VERSION ""

NS_ :

BS_:

BU_: Radar MABX

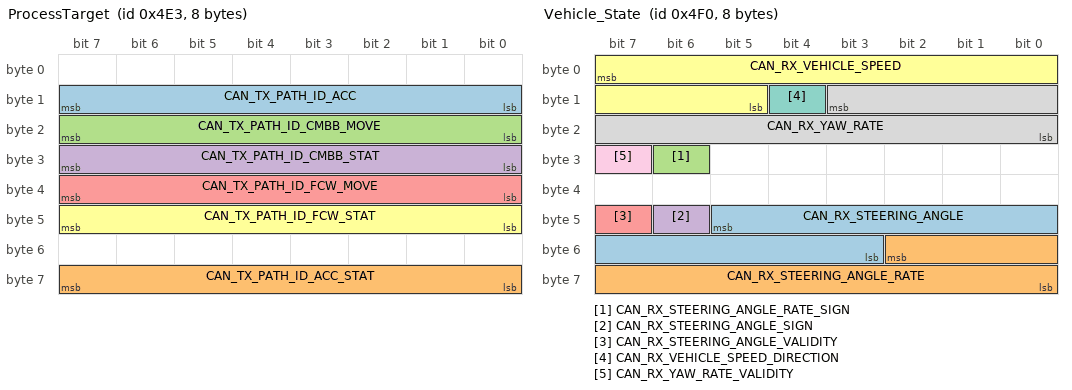
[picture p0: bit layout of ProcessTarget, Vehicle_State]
BO_ 1251 ProcessTarget: 8 Radar
 SG_ CAN_TX_PATH_ID_ACC : 15|8@0+ (1,0) [0|255] ""  MABX
 SG_ CAN_TX_PATH_ID_ACC_STAT : 63|8@0+ (1,0) [0|255] ""  MABX
 SG_ CAN_TX_PATH_ID_CMBB_MOVE : 23|8@0+ (1,0) [0|255] ""  MABX
 SG_ CAN_TX_PATH_ID_CMBB_STAT : 31|8@0+ (1,0) [0|255] ""  MABX
 SG_ CAN_TX_PATH_ID_FCW_MOVE : 39|8@0+ (1,0) [0|255] ""  MABX
 SG_ CAN_TX_PATH_ID_FCW_STAT : 47|8@0+ (1,0) [0|255] ""  MABX

BO_ 1264 Vehicle_State: 8 MABX
 SG_ CAN_RX_STEERING_ANGLE : 45|11@0+ (1,0) [0|2047] "deg"  Radar
 SG_ CAN_RX_STEERING_ANGLE_RATE : 50|11@0+ (1,0) [0|2047] "deg/s"  Radar
 SG_ CAN_RX_STEERING_ANGLE_RATE_SIGN : 30|1@0+ (1,0) [0|1] ""  Radar
 SG_ CAN_RX_STEERING_ANGLE_SIGN : 46|1@0+ (1,0) [0|1] ""  Radar
 SG_ CAN_RX_STEERING_ANGLE_VALIDITY : 47|1@0+ (1,0) [0|1] ""  Radar
 SG_ CAN_RX_VEHICLE_SPEED : 7|11@0+ (0.0625,0) [0|127.9375] "m/s"  Radar
 SG_ CAN_RX_VEHICLE_SPEED_DIRECTION : 12|1@0+ (1,0) [0|1] ""  Radar
 SG_ CAN_RX_YAW_RATE : 11|12@0- (0.0625,0) [-128|127.9375] "deg/s"  Radar
 SG_ CAN_RX_YAW_RATE_VALIDITY : 31|1@0+ (1,0) [0|1] ""  Radar

BO_ 1265 Radar_Lateral_Position: 8 MABX
 SG_ CAN_RX_LATERAL_MOUNTING_OFFSET : 47|8@0- (0.015625,0) [-1.9375|1.9375] "m"  Radar
 SG_ CAN_RX_VEHICLE_SPEED_VALIDITY : 61|1@0+ (1,0) [0|1] ""  Radar

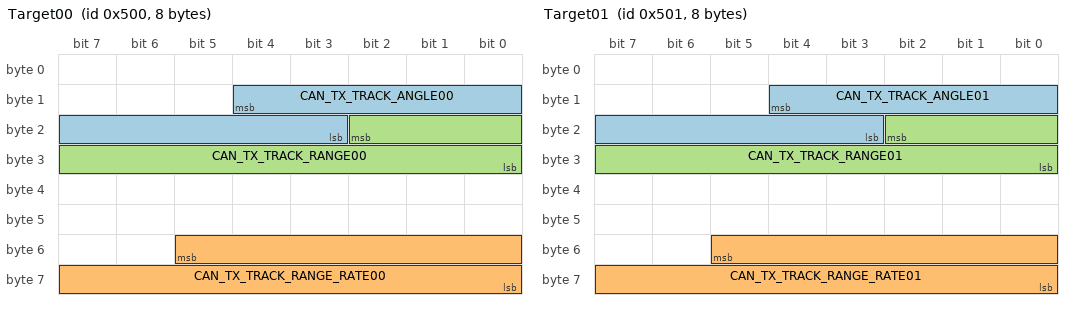
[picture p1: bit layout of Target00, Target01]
BO_ 1280 Target00: 8 Radar
 SG_ CAN_TX_TRACK_ANGLE00 : 12|10@0- (0.1,0) [-51.2|51.1] "deg"  MABX
 SG_ CAN_TX_TRACK_RANGE_RATE00 : 53|14@0- (0.01,0) [-81.92|81.92] "m/s"  MABX
 SG_ CAN_TX_TRACK_RANGE00 : 18|11@0+ (0.1,0) [0|204.7] "m"  MABX

BO_ 1281 Target01: 8 Radar
 SG_ CAN_TX_TRACK_ANGLE01 : 12|10@0- (0.1,0) [-51.2|51.1] "deg"  MABX
 SG_ CAN_TX_TRACK_RANGE_RATE01 : 53|14@0- (0.01,0) [-81.92|81.92] "m/s"  MABX
 SG_ CAN_TX_TRACK_RANGE01 : 18|11@0+ (0.1,0) [0|204.7] "m"  MABX

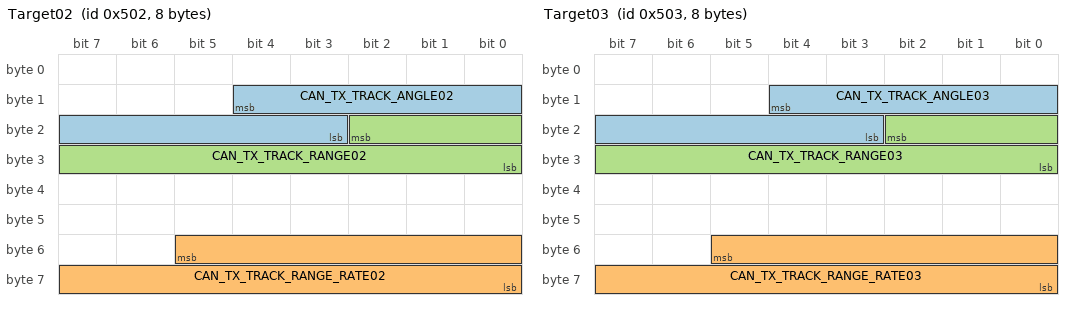
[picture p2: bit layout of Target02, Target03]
BO_ 1282 Target02: 8 Radar
 SG_ CAN_TX_TRACK_ANGLE02 : 12|10@0- (0.1,0) [-51.2|51.1] "deg"  MABX
 SG_ CAN_TX_TRACK_RANGE_RATE02 : 53|14@0- (0.01,0) [-81.92|81.92] "m/s"  MABX
 SG_ CAN_TX_TRACK_RANGE02 : 18|11@0+ (0.1,0) [0|204.7] "m"  MABX

BO_ 1283 Target03: 8 Radar
 SG_ CAN_TX_TRACK_ANGLE03 : 12|10@0- (0.1,0) [-51.2|51.1] "deg"  MABX
 SG_ CAN_TX_TRACK_RANGE_RATE03 : 53|14@0- (0.01,0) [-81.92|81.92] "m/s"  MABX
 SG_ CAN_TX_TRACK_RANGE03 : 18|11@0+ (0.1,0) [0|204.7] "m"  MABX

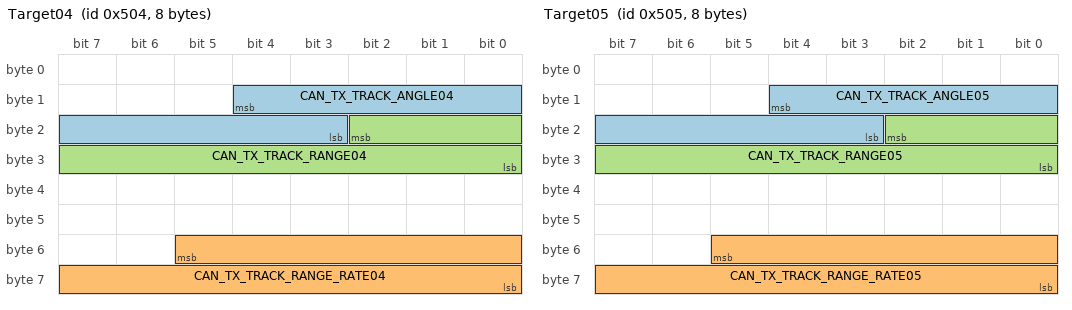
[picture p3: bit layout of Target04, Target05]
BO_ 1284 Target04: 8 Radar
 SG_ CAN_TX_TRACK_ANGLE04 : 12|10@0- (0.1,0) [-51.2|51.1] "deg"  MABX
 SG_ CAN_TX_TRACK_RANGE_RATE04 : 53|14@0- (0.01,0) [-81.92|81.92] "m/s"  MABX
 SG_ CAN_TX_TRACK_RANGE04 : 18|11@0+ (0.1,0) [0|204.7] "m"  MABX

BO_ 1285 Target05: 8 Radar
 SG_ CAN_TX_TRACK_ANGLE05 : 12|10@0- (0.1,0) [-51.2|51.1] "deg"  MABX
 SG_ CAN_TX_TRACK_RANGE_RATE05 : 53|14@0- (0.01,0) [-81.92|81.92] "m/s"  MABX
 SG_ CAN_TX_TRACK_RANGE05 : 18|11@0+ (0.1,0) [0|204.7] "m"  MABX

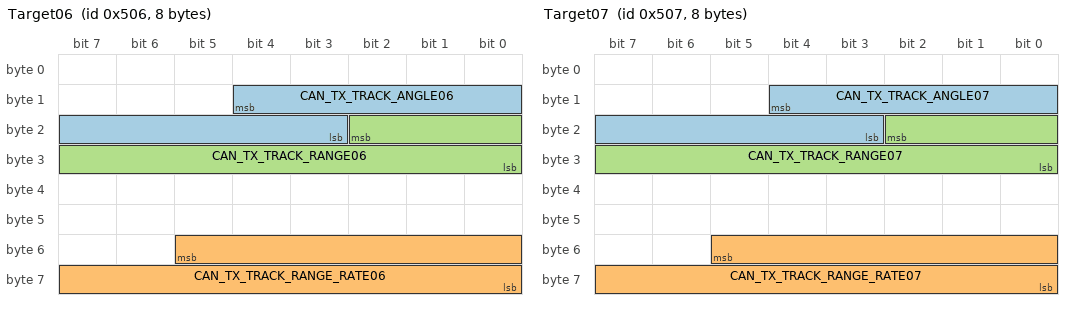
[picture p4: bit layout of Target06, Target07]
BO_ 1286 Target06: 8 Radar
 SG_ CAN_TX_TRACK_ANGLE06 : 12|10@0- (0.1,0) [-51.2|51.1] "deg"  MABX
 SG_ CAN_TX_TRACK_RANGE_RATE06 : 53|14@0- (0.01,0) [-81.92|81.92] "m/s"  MABX
 SG_ CAN_TX_TRACK_RANGE06 : 18|11@0+ (0.1,0) [0|204.7] "m"  MABX

BO_ 1287 Target07: 8 Radar
 SG_ CAN_TX_TRACK_ANGLE07 : 12|10@0- (0.1,0) [-51.2|51.1] "deg"  MABX
 SG_ CAN_TX_TRACK_RANGE_RATE07 : 53|14@0- (0.01,0) [-81.92|81.92] "m/s"  MABX
 SG_ CAN_TX_TRACK_RANGE07 : 18|11@0+ (0.1,0) [0|204.7] "m"  MABX

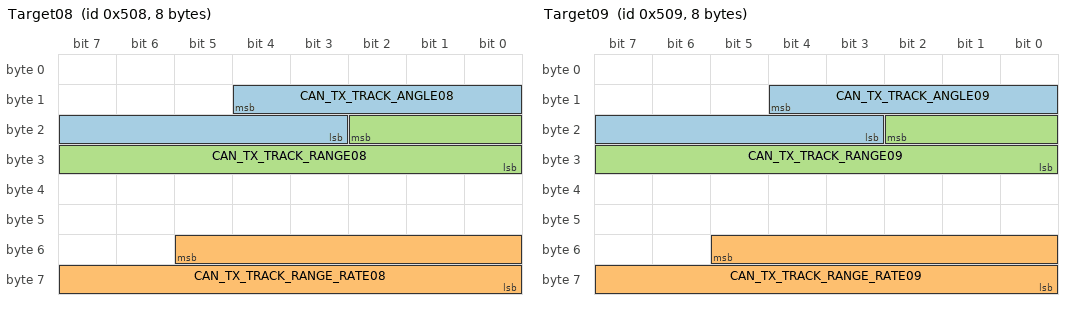
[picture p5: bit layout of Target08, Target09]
BO_ 1288 Target08: 8 Radar
 SG_ CAN_TX_TRACK_ANGLE08 : 12|10@0- (0.1,0) [-51.2|51.1] "deg"  MABX
 SG_ CAN_TX_TRACK_RANGE_RATE08 : 53|14@0- (0.01,0) [-81.92|81.92] "m/s"  MABX
 SG_ CAN_TX_TRACK_RANGE08 : 18|11@0+ (0.1,0) [0|204.7] "m"  MABX

BO_ 1289 Target09: 8 Radar
 SG_ CAN_TX_TRACK_ANGLE09 : 12|10@0- (0.1,0) [-51.2|51.1] "deg"  MABX
 SG_ CAN_TX_TRACK_RANGE_RATE09 : 53|14@0- (0.01,0) [-81.92|81.92] "m/s"  MABX
 SG_ CAN_TX_TRACK_RANGE09 : 18|11@0+ (0.1,0) [0|204.7] "m"  MABX

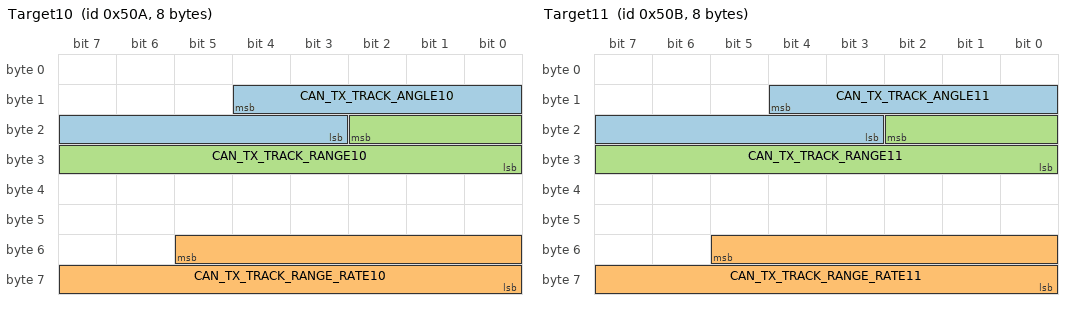
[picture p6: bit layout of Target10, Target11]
BO_ 1290 Target10: 8 Radar
 SG_ CAN_TX_TRACK_ANGLE10 : 12|10@0- (0.1,0) [-51.2|51.1] "deg"  MABX
 SG_ CAN_TX_TRACK_RANGE_RATE10 : 53|14@0- (0.01,0) [-81.92|81.92] "m/s"  MABX
 SG_ CAN_TX_TRACK_RANGE10 : 18|11@0+ (0.1,0) [0|204.7] "m"  MABX

BO_ 1291 Target11: 8 Radar
 SG_ CAN_TX_TRACK_ANGLE11 : 12|10@0- (0.1,0) [-51.2|51.1] "deg"  MABX
 SG_ CAN_TX_TRACK_RANGE_RATE11 : 53|14@0- (0.01,0) [-81.92|81.92] "m/s"  MABX
 SG_ CAN_TX_TRACK_RANGE11 : 18|11@0+ (0.1,0) [0|204.7] "m"  MABX

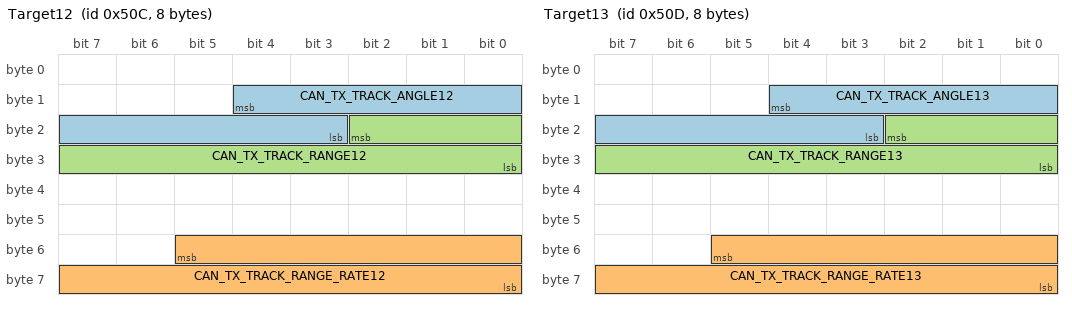
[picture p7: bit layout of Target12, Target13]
BO_ 1292 Target12: 8 Radar
 SG_ CAN_TX_TRACK_ANGLE12 : 12|10@0- (0.1,0) [-51.2|51.1] "deg"  MABX
 SG_ CAN_TX_TRACK_RANGE_RATE12 : 53|14@0- (0.01,0) [-81.92|81.92] "m/s"  MABX
 SG_ CAN_TX_TRACK_RANGE12 : 18|11@0+ (0.1,0) [0|204.7] "m"  MABX

BO_ 1293 Target13: 8 Radar
 SG_ CAN_TX_TRACK_ANGLE13 : 12|10@0- (0.1,0) [-51.2|51.1] "deg"  MABX
 SG_ CAN_TX_TRACK_RANGE_RATE13 : 53|14@0- (0.01,0) [-81.92|81.92] "m/s"  MABX
 SG_ CAN_TX_TRACK_RANGE13 : 18|11@0+ (0.1,0) [0|204.7] "m"  MABX

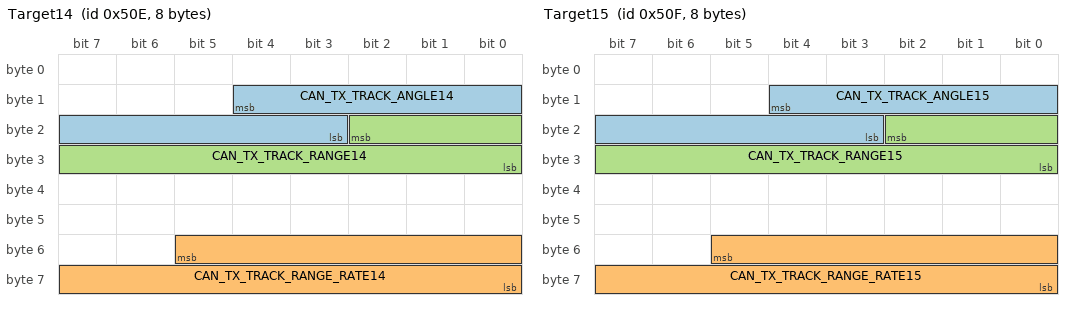
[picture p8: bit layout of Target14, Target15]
BO_ 1294 Target14: 8 Radar
 SG_ CAN_TX_TRACK_ANGLE14 : 12|10@0- (0.1,0) [-51.2|51.1] "deg"  MABX
 SG_ CAN_TX_TRACK_RANGE_RATE14 : 53|14@0- (0.01,0) [-81.92|81.92] "m/s"  MABX
 SG_ CAN_TX_TRACK_RANGE14 : 18|11@0+ (0.1,0) [0|204.7] "m"  MABX

BO_ 1295 Target15: 8 Radar
 SG_ CAN_TX_TRACK_ANGLE15 : 12|10@0- (0.1,0) [-51.2|51.1] "deg"  MABX
 SG_ CAN_TX_TRACK_RANGE_RATE15 : 53|14@0- (0.01,0) [-81.92|81.92] "m/s"  MABX
 SG_ CAN_TX_TRACK_RANGE15 : 18|11@0+ (0.1,0) [0|204.7] "m"  MABX

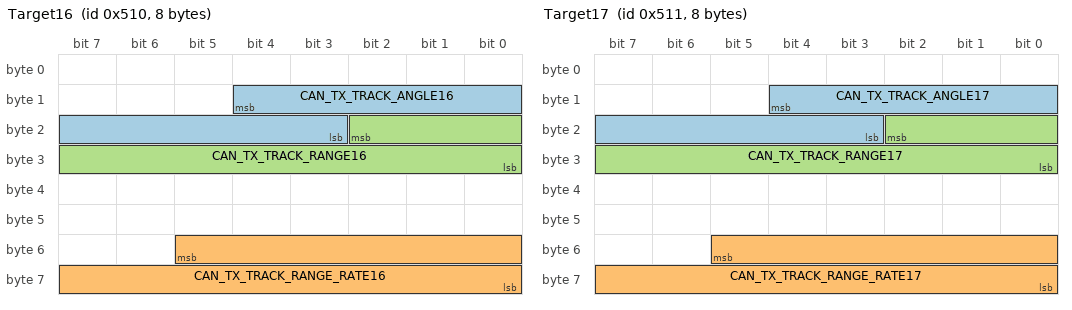
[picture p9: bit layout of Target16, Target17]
BO_ 1296 Target16: 8 Radar
 SG_ CAN_TX_TRACK_ANGLE16 : 12|10@0- (0.1,0) [-51.2|51.1] "deg"  MABX
 SG_ CAN_TX_TRACK_RANGE_RATE16 : 53|14@0- (0.01,0) [-81.92|81.92] "m/s"  MABX
 SG_ CAN_TX_TRACK_RANGE16 : 18|11@0+ (0.1,0) [0|204.7] "m"  MABX

BO_ 1297 Target17: 8 Radar
 SG_ CAN_TX_TRACK_ANGLE17 : 12|10@0- (0.1,0) [-51.2|51.1] "deg"  MABX
 SG_ CAN_TX_TRACK_RANGE_RATE17 : 53|14@0- (0.01,0) [-81.92|81.92] "m/s"  MABX
 SG_ CAN_TX_TRACK_RANGE17 : 18|11@0+ (0.1,0) [0|204.7] "m"  MABX

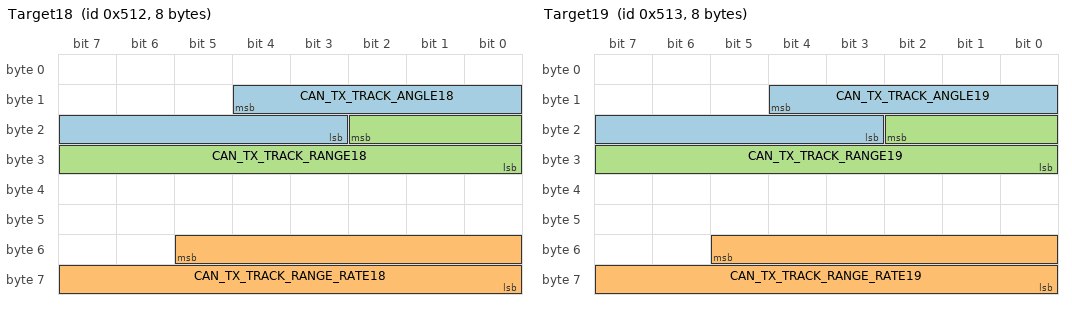
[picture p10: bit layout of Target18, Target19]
BO_ 1298 Target18: 8 Radar
 SG_ CAN_TX_TRACK_ANGLE18 : 12|10@0- (0.1,0) [-51.2|51.1] "deg"  MABX
 SG_ CAN_TX_TRACK_RANGE_RATE18 : 53|14@0- (0.01,0) [-81.92|81.92] "m/s"  MABX
 SG_ CAN_TX_TRACK_RANGE18 : 18|11@0+ (0.1,0) [0|204.7] "m"  MABX

BO_ 1299 Target19: 8 Radar
 SG_ CAN_TX_TRACK_ANGLE19 : 12|10@0- (0.1,0) [-51.2|51.1] "deg"  MABX
 SG_ CAN_TX_TRACK_RANGE_RATE19 : 53|14@0- (0.01,0) [-81.92|81.92] "m/s"  MABX
 SG_ CAN_TX_TRACK_RANGE19 : 18|11@0+ (0.1,0) [0|204.7] "m"  MABX

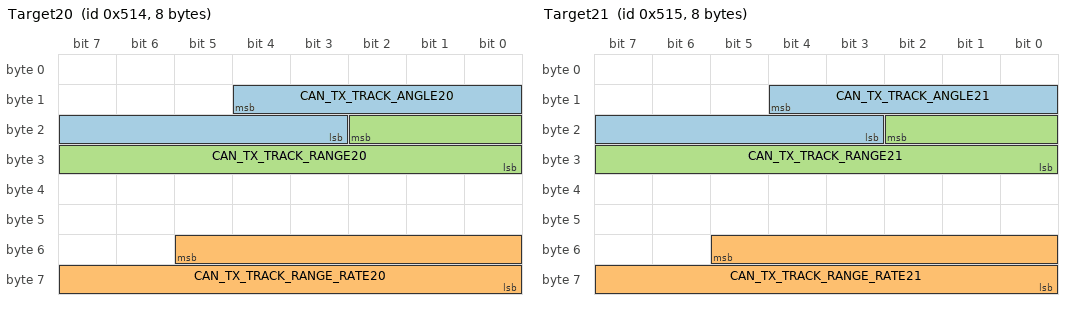
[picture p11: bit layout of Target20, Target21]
BO_ 1300 Target20: 8 Radar
 SG_ CAN_TX_TRACK_ANGLE20 : 12|10@0- (0.1,0) [-51.2|51.1] "deg"  MABX
 SG_ CAN_TX_TRACK_RANGE_RATE20 : 53|14@0- (0.01,0) [-81.92|81.92] "m/s"  MABX
 SG_ CAN_TX_TRACK_RANGE20 : 18|11@0+ (0.1,0) [0|204.7] "m"  MABX

BO_ 1301 Target21: 8 Radar
 SG_ CAN_TX_TRACK_ANGLE21 : 12|10@0- (0.1,0) [-51.2|51.1] "deg"  MABX
 SG_ CAN_TX_TRACK_RANGE_RATE21 : 53|14@0- (0.01,0) [-81.92|81.92] "m/s"  MABX
 SG_ CAN_TX_TRACK_RANGE21 : 18|11@0+ (0.1,0) [0|204.7] "m"  MABX

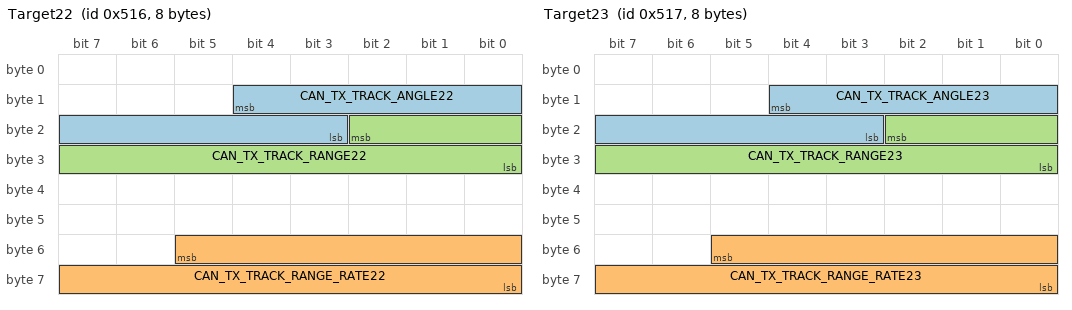
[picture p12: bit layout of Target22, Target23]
BO_ 1302 Target22: 8 Radar
 SG_ CAN_TX_TRACK_ANGLE22 : 12|10@0- (0.1,0) [-51.2|51.1] "deg"  MABX
 SG_ CAN_TX_TRACK_RANGE_RATE22 : 53|14@0- (0.01,0) [-81.92|81.92] "m/s"  MABX
 SG_ CAN_TX_TRACK_RANGE22 : 18|11@0+ (0.1,0) [0|204.7] "m"  MABX

BO_ 1303 Target23: 8 Radar
 SG_ CAN_TX_TRACK_ANGLE23 : 12|10@0- (0.1,0) [-51.2|51.1] "deg"  MABX
 SG_ CAN_TX_TRACK_RANGE_RATE23 : 53|14@0- (0.01,0) [-81.92|81.92] "m/s"  MABX
 SG_ CAN_TX_TRACK_RANGE23 : 18|11@0+ (0.1,0) [0|204.7] "m"  MABX

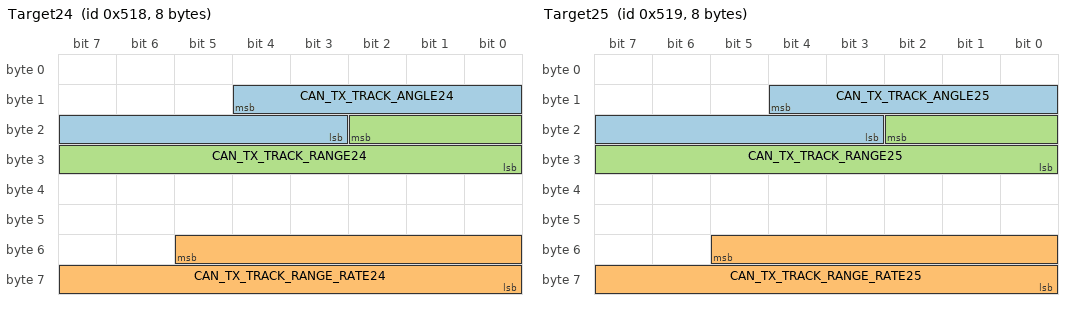
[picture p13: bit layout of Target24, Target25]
BO_ 1304 Target24: 8 Radar
 SG_ CAN_TX_TRACK_ANGLE24 : 12|10@0- (0.1,0) [-51.2|51.1] "deg"  MABX
 SG_ CAN_TX_TRACK_RANGE_RATE24 : 53|14@0- (0.01,0) [-81.92|81.92] "m/s"  MABX
 SG_ CAN_TX_TRACK_RANGE24 : 18|11@0+ (0.1,0) [0|204.7] "m"  MABX

BO_ 1305 Target25: 8 Radar
 SG_ CAN_TX_TRACK_ANGLE25 : 12|10@0- (0.1,0) [-51.2|51.1] "deg"  MABX
 SG_ CAN_TX_TRACK_RANGE_RATE25 : 53|14@0- (0.01,0) [-81.92|81.92] "m/s"  MABX
 SG_ CAN_TX_TRACK_RANGE25 : 18|11@0+ (0.1,0) [0|204.7] "m"  MABX

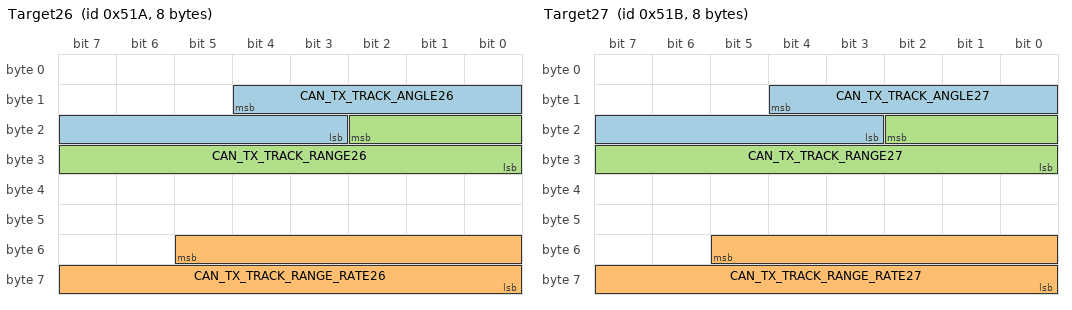
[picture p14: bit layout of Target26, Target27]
BO_ 1306 Target26: 8 Radar
 SG_ CAN_TX_TRACK_ANGLE26 : 12|10@0- (0.1,0) [-51.2|51.1] "deg"  MABX
 SG_ CAN_TX_TRACK_RANGE_RATE26 : 53|14@0- (0.01,0) [-81.92|81.92] "m/s"  MABX
 SG_ CAN_TX_TRACK_RANGE26 : 18|11@0+ (0.1,0) [0|204.7] "m"  MABX

BO_ 1307 Target27: 8 Radar
 SG_ CAN_TX_TRACK_ANGLE27 : 12|10@0- (0.1,0) [-51.2|51.1] "deg"  MABX
 SG_ CAN_TX_TRACK_RANGE_RATE27 : 53|14@0- (0.01,0) [-81.92|81.92] "m/s"  MABX
 SG_ CAN_TX_TRACK_RANGE27 : 18|11@0+ (0.1,0) [0|204.7] "m"  MABX

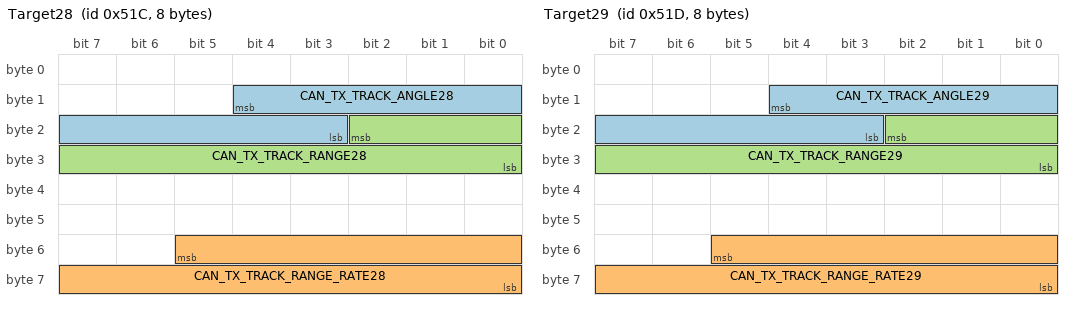
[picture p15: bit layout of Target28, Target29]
BO_ 1308 Target28: 8 Radar
 SG_ CAN_TX_TRACK_ANGLE28 : 12|10@0- (0.1,0) [-51.2|51.1] "deg"  MABX
 SG_ CAN_TX_TRACK_RANGE_RATE28 : 53|14@0- (0.01,0) [-81.92|81.92] "m/s"  MABX
 SG_ CAN_TX_TRACK_RANGE28 : 18|11@0+ (0.1,0) [0|204.7] "m"  MABX

BO_ 1309 Target29: 8 Radar
 SG_ CAN_TX_TRACK_ANGLE29 : 12|10@0- (0.1,0) [-51.2|51.1] "deg"  MABX
 SG_ CAN_TX_TRACK_RANGE_RATE29 : 53|14@0- (0.01,0) [-81.92|81.92] "m/s"  MABX
 SG_ CAN_TX_TRACK_RANGE29 : 18|11@0+ (0.1,0) [0|204.7] "m"  MABX

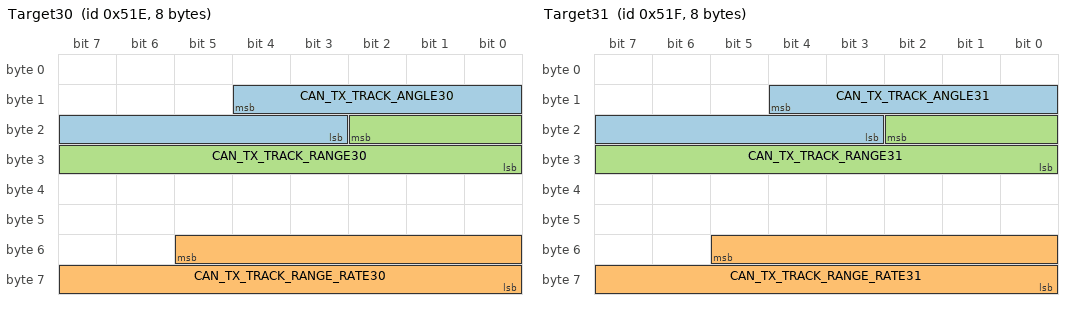
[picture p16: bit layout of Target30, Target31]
BO_ 1310 Target30: 8 Radar
 SG_ CAN_TX_TRACK_ANGLE30 : 12|10@0- (0.1,0) [-51.2|51.1] "deg"  MABX
 SG_ CAN_TX_TRACK_RANGE_RATE30 : 53|14@0- (0.01,0) [-81.92|81.92] "m/s"  MABX
 SG_ CAN_TX_TRACK_RANGE30 : 18|11@0+ (0.1,0) [0|204.7] "m"  MABX

BO_ 1311 Target31: 8 Radar
 SG_ CAN_TX_TRACK_ANGLE31 : 12|10@0- (0.1,0) [-51.2|51.1] "deg"  MABX
 SG_ CAN_TX_TRACK_RANGE_RATE31 : 53|14@0- (0.01,0) [-81.92|81.92] "m/s"  MABX
 SG_ CAN_TX_TRACK_RANGE31 : 18|11@0+ (0.1,0) [0|204.7] "m"  MABX

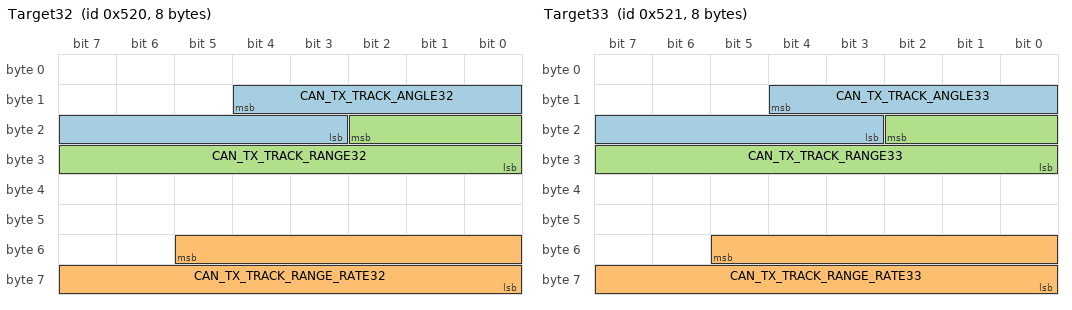
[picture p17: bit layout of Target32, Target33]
BO_ 1312 Target32: 8 Radar
 SG_ CAN_TX_TRACK_ANGLE32 : 12|10@0- (0.1,0) [-51.2|51.1] "deg"  MABX
 SG_ CAN_TX_TRACK_RANGE_RATE32 : 53|14@0- (0.01,0) [-81.92|81.92] "m/s"  MABX
 SG_ CAN_TX_TRACK_RANGE32 : 18|11@0+ (0.1,0) [0|204.7] "m"  MABX

BO_ 1313 Target33: 8 Radar
 SG_ CAN_TX_TRACK_ANGLE33 : 12|10@0- (0.1,0) [-51.2|51.1] "deg"  MABX
 SG_ CAN_TX_TRACK_RANGE_RATE33 : 53|14@0- (0.01,0) [-81.92|81.92] "m/s"  MABX
 SG_ CAN_TX_TRACK_RANGE33 : 18|11@0+ (0.1,0) [0|204.7] "m"  MABX

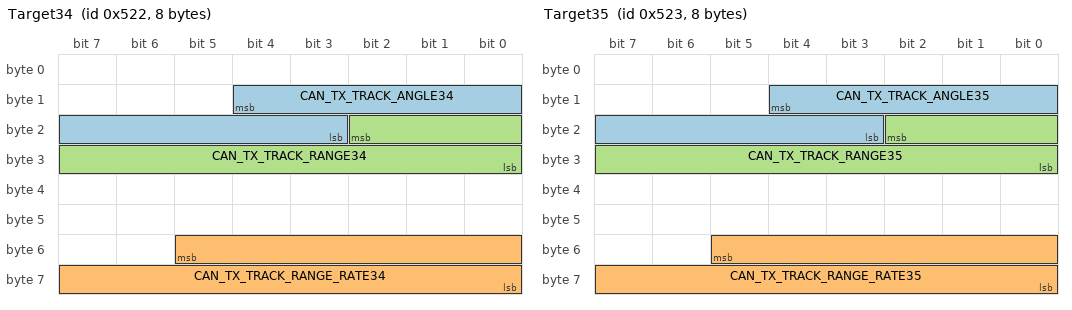
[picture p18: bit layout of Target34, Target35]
BO_ 1314 Target34: 8 Radar
 SG_ CAN_TX_TRACK_ANGLE34 : 12|10@0- (0.1,0) [-51.2|51.1] "deg"  MABX
 SG_ CAN_TX_TRACK_RANGE_RATE34 : 53|14@0- (0.01,0) [-81.92|81.92] "m/s"  MABX
 SG_ CAN_TX_TRACK_RANGE34 : 18|11@0+ (0.1,0) [0|204.7] "m"  MABX

BO_ 1315 Target35: 8 Radar
 SG_ CAN_TX_TRACK_ANGLE35 : 12|10@0- (0.1,0) [-51.2|51.1] "deg"  MABX
 SG_ CAN_TX_TRACK_RANGE_RATE35 : 53|14@0- (0.01,0) [-81.92|81.92] "m/s"  MABX
 SG_ CAN_TX_TRACK_RANGE35 : 18|11@0+ (0.1,0) [0|204.7] "m"  MABX

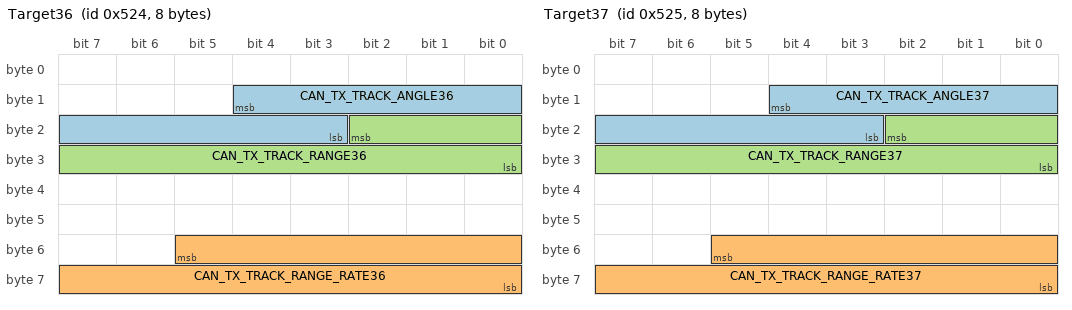
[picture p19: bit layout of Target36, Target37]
BO_ 1316 Target36: 8 Radar
 SG_ CAN_TX_TRACK_ANGLE36 : 12|10@0- (0.1,0) [-51.2|51.1] "deg"  MABX
 SG_ CAN_TX_TRACK_RANGE_RATE36 : 53|14@0- (0.01,0) [-81.92|81.92] "m/s"  MABX
 SG_ CAN_TX_TRACK_RANGE36 : 18|11@0+ (0.1,0) [0|204.7] "m"  MABX

BO_ 1317 Target37: 8 Radar
 SG_ CAN_TX_TRACK_ANGLE37 : 12|10@0- (0.1,0) [-51.2|51.1] "deg"  MABX
 SG_ CAN_TX_TRACK_RANGE_RATE37 : 53|14@0- (0.01,0) [-81.92|81.92] "m/s"  MABX
 SG_ CAN_TX_TRACK_RANGE37 : 18|11@0+ (0.1,0) [0|204.7] "m"  MABX

BO_ 1318 Target38: 8 Radar
 SG_ CAN_TX_TRACK_ANGLE38 : 12|10@0- (0.1,0) [-51.2|51.1] "deg"  MABX
 SG_ CAN_TX_TRACK_RANGE_RATE38 : 53|14@0- (0.01,0) [-81.92|81.92] "m/s"  MABX
 SG_ CAN_TX_TRACK_RANGE38 : 18|11@0+ (0.1,0) [0|204.7] "m"  MABX

BO_ 1319 Target39: 8 Radar
 SG_ CAN_TX_TRACK_ANGLE39 : 12|10@0- (0.1,0) [-51.2|51.1] "deg"  MABX
 SG_ CAN_TX_TRACK_RANGE_RATE39 : 53|14@0- (0.01,0) [-81.92|81.92] "m/s"  MABX
 SG_ CAN_TX_TRACK_RANGE39 : 18|11@0+ (0.1,0) [0|204.7] "m"  MABX

BO_ 1320 Target40: 8 Radar
 SG_ CAN_TX_TRACK_ANGLE40 : 12|10@0- (0.1,0) [-51.2|51.1] "deg"  MABX
 SG_ CAN_TX_TRACK_RANGE_RATE40 : 53|14@0- (0.01,0) [-81.92|81.92] "m/s"  MABX
 SG_ CAN_TX_TRACK_RANGE40 : 18|11@0+ (0.1,0) [0|204.7] "m"  MABX

BO_ 1321 Target41: 8 Radar
 SG_ CAN_TX_TRACK_ANGLE41 : 12|10@0- (0.1,0) [-51.2|51.1] "deg"  MABX
 SG_ CAN_TX_TRACK_RANGE_RATE41 : 53|14@0- (0.01,0) [-81.92|81.92] "m/s"  MABX
 SG_ CAN_TX_TRACK_RANGE41 : 18|11@0+ (0.1,0) [0|204.7] "m"  MABX

BO_ 1322 Target42: 8 Radar
 SG_ CAN_TX_TRACK_ANGLE42 : 12|10@0- (0.1,0) [-51.2|51.1] "deg"  MABX
 SG_ CAN_TX_TRACK_RANGE_RATE42 : 53|14@0- (0.01,0) [-81.92|81.92] "m/s"  MABX
 SG_ CAN_TX_TRACK_RANGE42 : 18|11@0+ (0.1,0) [0|204.7] "m"  MABX

BO_ 1323 Target43: 8 Radar
 SG_ CAN_TX_TRACK_ANGLE43 : 12|10@0- (0.1,0) [-51.2|51.1] "deg"  MABX
 SG_ CAN_TX_TRACK_RANGE_RATE43 : 53|14@0- (0.01,0) [-81.92|81.92] "m/s"  MABX
 SG_ CAN_TX_TRACK_RANGE43 : 18|11@0+ (0.1,0) [0|204.7] "m"  MABX

BO_ 1324 Target44: 8 Radar
 SG_ CAN_TX_TRACK_ANGLE44 : 12|10@0- (0.1,0) [-51.2|51.1] "deg"  MABX
 SG_ CAN_TX_TRACK_RANGE_RATE44 : 53|14@0- (0.01,0) [-81.92|81.92] "m/s"  MABX
 SG_ CAN_TX_TRACK_RANGE44 : 18|11@0+ (0.1,0) [0|204.7] "m"  MABX

BO_ 1325 Target45: 8 Radar
 SG_ CAN_TX_TRACK_ANGLE45 : 12|10@0- (0.1,0) [-51.2|51.1] "deg"  MABX
 SG_ CAN_TX_TRACK_RANGE_RATE45 : 53|14@0- (0.01,0) [-81.92|81.92] "m/s"  MABX
 SG_ CAN_TX_TRACK_RANGE45 : 18|11@0+ (0.1,0) [0|204.7] "m"  MABX

BO_ 1326 Target46: 8 Radar
 SG_ CAN_TX_TRACK_ANGLE46 : 12|10@0- (0.1,0) [-51.2|51.1] "deg"  MABX
 SG_ CAN_TX_TRACK_RANGE_RATE46 : 53|14@0- (0.01,0) [-81.92|81.92] "m/s"  MABX
 SG_ CAN_TX_TRACK_RANGE46 : 18|11@0+ (0.1,0) [0|204.7] "m"  MABX

BO_ 1327 Target47: 8 Radar
 SG_ CAN_TX_TRACK_ANGLE47 : 12|10@0- (0.1,0) [-51.2|51.1] "deg"  MABX
 SG_ CAN_TX_TRACK_RANGE_RATE47 : 53|14@0- (0.01,0) [-81.92|81.92] "m/s"  MABX
 SG_ CAN_TX_TRACK_RANGE47 : 18|11@0+ (0.1,0) [0|204.7] "m"  MABX

BO_ 1328 Target48: 8 Radar
 SG_ CAN_TX_TRACK_ANGLE48 : 12|10@0- (0.1,0) [-51.2|51.1] "deg"  MABX
 SG_ CAN_TX_TRACK_RANGE_RATE48 : 53|14@0- (0.01,0) [-81.92|81.92] "m/s"  MABX
 SG_ CAN_TX_TRACK_RANGE48 : 18|11@0+ (0.1,0) [0|204.7] "m"  MABX

BO_ 1329 Target49: 8 Radar
 SG_ CAN_TX_TRACK_ANGLE49 : 12|10@0- (0.1,0) [-51.2|51.1] "deg"  MABX
 SG_ CAN_TX_TRACK_RANGE_RATE49 : 53|14@0- (0.01,0) [-81.92|81.92] "m/s"  MABX
 SG_ CAN_TX_TRACK_RANGE49 : 18|11@0+ (0.1,0) [0|204.7] "m"  MABX

BO_ 1330 Target50: 8 Radar
 SG_ CAN_TX_TRACK_ANGLE50 : 12|10@0- (0.1,0) [-51.2|51.1] "deg"  MABX
 SG_ CAN_TX_TRACK_RANGE_RATE50 : 53|14@0- (0.01,0) [-81.92|81.92] "m/s"  MABX
 SG_ CAN_TX_TRACK_RANGE50 : 18|11@0+ (0.1,0) [0|204.7] "m"  MABX

BO_ 1331 Target51: 8 Radar
 SG_ CAN_TX_TRACK_ANGLE51 : 12|10@0- (0.1,0) [-51.2|51.1] "deg"  MABX
 SG_ CAN_TX_TRACK_RANGE_RATE51 : 53|14@0- (0.01,0) [-81.92|81.92] "m/s"  MABX
 SG_ CAN_TX_TRACK_RANGE51 : 18|11@0+ (0.1,0) [0|204.7] "m"  MABX

BO_ 1332 Target52: 8 Radar
 SG_ CAN_TX_TRACK_ANGLE52 : 12|10@0- (0.1,0) [-51.2|51.1] "deg"  MABX
 SG_ CAN_TX_TRACK_RANGE_RATE52 : 53|14@0- (0.01,0) [-81.92|81.92] "m/s"  MABX
 SG_ CAN_TX_TRACK_RANGE52 : 18|11@0+ (0.1,0) [0|204.7] "m"  MABX

BO_ 1333 Target53: 8 Radar
 SG_ CAN_TX_TRACK_ANGLE53 : 12|10@0- (0.1,0) [-51.2|51.1] "deg"  MABX
 SG_ CAN_TX_TRACK_RANGE_RATE53 : 53|14@0- (0.01,0) [-81.92|81.92] "m/s"  MABX
 SG_ CAN_TX_TRACK_RANGE53 : 18|11@0+ (0.1,0) [0|204.7] "m"  MABX

BO_ 1334 Target54: 8 Radar
 SG_ CAN_TX_TRACK_ANGLE54 : 12|10@0- (0.1,0) [-51.2|51.1] "deg"  MABX
 SG_ CAN_TX_TRACK_RANGE_RATE54 : 53|14@0- (0.01,0) [-81.92|81.92] "m/s"  MABX
 SG_ CAN_TX_TRACK_RANGE54 : 18|11@0+ (0.1,0) [0|204.7] "m"  MABX

BO_ 1335 Target55: 8 Radar
 SG_ CAN_TX_TRACK_ANGLE55 : 12|10@0- (0.1,0) [-51.2|51.1] "deg"  MABX
 SG_ CAN_TX_TRACK_RANGE_RATE55 : 53|14@0- (0.01,0) [-81.92|81.92] "m/s"  MABX
 SG_ CAN_TX_TRACK_RANGE55 : 18|11@0+ (0.1,0) [0|204.7] "m"  MABX

BO_ 1336 Target56: 8 Radar
 SG_ CAN_TX_TRACK_ANGLE56 : 12|10@0- (0.1,0) [-51.2|51.1] "deg"  MABX
 SG_ CAN_TX_TRACK_RANGE_RATE56 : 53|14@0- (0.01,0) [-81.92|81.92] "m/s"  MABX
 SG_ CAN_TX_TRACK_RANGE56 : 18|11@0+ (0.1,0) [0|204.7] "m"  MABX

BO_ 1337 Target57: 8 Radar
 SG_ CAN_TX_TRACK_ANGLE57 : 12|10@0- (0.1,0) [-51.2|51.1] "deg"  MABX
 SG_ CAN_TX_TRACK_RANGE_RATE57 : 53|14@0- (0.01,0) [-81.92|81.92] "m/s"  MABX
 SG_ CAN_TX_TRACK_RANGE57 : 18|11@0+ (0.1,0) [0|204.7] "m"  MABX

BO_ 1338 Target58: 8 Radar
 SG_ CAN_TX_TRACK_ANGLE58 : 12|10@0- (0.1,0) [-51.2|51.1] "deg"  MABX
 SG_ CAN_TX_TRACK_RANGE_RATE58 : 53|14@0- (0.01,0) [-81.92|81.92] "m/s"  MABX
 SG_ CAN_TX_TRACK_RANGE58 : 18|11@0+ (0.1,0) [0|204.7] "m"  MABX

BO_ 1339 Target59: 8 Radar
 SG_ CAN_TX_TRACK_ANGLE59 : 12|10@0- (0.1,0) [-51.2|51.1] "deg"  MABX
 SG_ CAN_TX_TRACK_RANGE_RATE59 : 53|14@0- (0.01,0) [-81.92|81.92] "m/s"  MABX
 SG_ CAN_TX_TRACK_RANGE59 : 18|11@0+ (0.1,0) [0|204.7] "m"  MABX

BO_ 1340 Target60: 8 Radar
 SG_ CAN_TX_TRACK_ANGLE60 : 12|10@0- (0.1,0) [-51.2|51.1] "deg"  MABX
 SG_ CAN_TX_TRACK_RANGE_RATE60 : 53|14@0- (0.01,0) [-81.92|81.92] "m/s"  MABX
 SG_ CAN_TX_TRACK_RANGE60 : 18|11@0+ (0.1,0) [0|204.7] "m"  MABX

BO_ 1341 Target61: 8 Radar
 SG_ CAN_TX_TRACK_ANGLE61 : 12|10@0- (0.1,0) [-51.2|51.1] "deg"  MABX
 SG_ CAN_TX_TRACK_RANGE_RATE61 : 53|14@0- (0.01,0) [-81.92|81.92] "m/s"  MABX
 SG_ CAN_TX_TRACK_RANGE61 : 18|11@0+ (0.1,0) [0|204.7] "m"  MABX

BO_ 1342 Target62: 8 Radar
 SG_ CAN_TX_TRACK_ANGLE62 : 12|10@0- (0.1,0) [-51.2|51.1] "deg"  MABX
 SG_ CAN_TX_TRACK_RANGE_RATE62 : 53|14@0- (0.01,0) [-81.92|81.92] "m/s"  MABX
 SG_ CAN_TX_TRACK_RANGE62 : 18|11@0+ (0.1,0) [0|204.7] "m"  MABX

BO_ 1343 Target63: 8 Radar
 SG_ CAN_TX_TRACK_ANGLE63 : 12|10@0- (0.1,0) [-51.2|51.1] "deg"  MABX
 SG_ CAN_TX_TRACK_RANGE_RATE63 : 53|14@0- (0.01,0) [-81.92|81.92] "m/s"  MABX
 SG_ CAN_TX_TRACK_RANGE63 : 18|11@0+ (0.1,0) [0|204.7] "m"  MABX

BO_ 1522 Radar_Vertical_Position: 8 MABX
 SG_ CAN_RX_RADAR_HEIGHT : 38|7@0+ (1,0) [0|125] "cm"  Radar

VAL_ 1264 CAN_RX_STEERING_ANGLE_RATE_SIGN 0 "left" 1 "right" ;
VAL_ 1264 CAN_RX_STEERING_ANGLE_SIGN 0 "left" 1 "right" ;
VAL_ 1264 CAN_RX_STEERING_ANGLE_VALIDITY 0 "invalid" 1 "valid" ;
VAL_ 1264 CAN_RX_VEHICLE_SPEED_DIRECTION 0 "Forward" 1 "Reverse" ;
VAL_ 1264 CAN_RX_YAW_RATE_VALIDITY 0 "invalid" 1 "valid" ;
VAL_ 1265 CAN_RX_VEHICLE_SPEED_VALIDITY 0 "invalid" 1 "valid" ;
